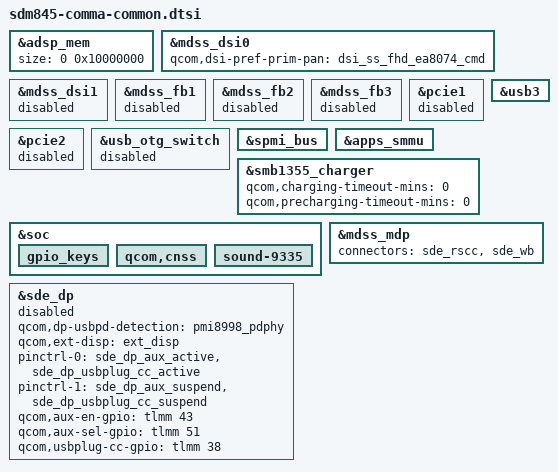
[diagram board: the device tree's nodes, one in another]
/*
 * Copyright (C) 2018, Comma.ai, Inc.
 *
 * This program is free software; you can redistribute it and/or modify
 * it under the terms of the GNU General Public License version 2 and
 * only version 2 as published by the Free Software Foundation.
 *
 * This program is distributed in the hope that it will be useful,
 * but WITHOUT ANY WARRANTY; without even the implied warranty of
 * MERCHANTABILITY or FITNESS FOR A PARTICULAR PURPOSE.  See the
 * GNU General Public License for more details.
 */

&adsp_mem {
	size = <0 0x10000000>;
};

&mdss_dsi0 {
	/delete-property/ qcom,platform-bklight-en-gpio;
};

&mdss_dsi1 {
	status = "disabled";
};

&mdss_fb1 {
	status = "disabled";
};

&mdss_fb2 {
	status = "disabled";
};

&mdss_fb3 {
	status = "disabled";
};


&pcie1 {
	status = "disabled";
};

&pcie2 {
	status = "disabled";
};


&usb3 {
	/delete-property/ vbus_dwc3-supply;
};

&usb_otg_switch {
	status = "disabled";
};

&spmi_bus {
	/delete-property/ qcom,enable-ahb-bus-workaround;
};

&apps_smmu {
	/delete-property/ qcom,no-asid-retention;
};

&smb1355_charger {
	qcom,charging-timeout-mins = <0>;
	qcom,precharging-timeout-mins = <0>;
};

&soc {
	/delete-node/ gen-vkeys;

	gpio_keys {
		/delete-node/ cam_focus;
		/delete-node/ cam_snapshot;
	};

	qcom,cnss {
		/delete-property/ qcom,wlan-ramdump-dynamic;
	};

	sound-9335 {
		/delete-property/ qcom,hph-en0-gpio;
		/delete-property/ qcom,hph-en1-gpio;
		/delete-property/ qcom,us-euro-gpios;
		/delete-property/ qcom,wsa-aux-dev-prefix;
		/delete-property/ qcom,wsa-devs;
		/delete-property/ qcom,wsa-max-devs;
	};
};

&sde_dp {
	status = "disabled";
	qcom,dp-usbpd-detection = <&pmi8998_pdphy>;
	qcom,ext-disp = <&ext_disp>;

	pinctrl-names = "mdss_dp_active", "mdss_dp_sleep";
	pinctrl-0 = <&sde_dp_aux_active &sde_dp_usbplug_cc_active>;
	pinctrl-1 = <&sde_dp_aux_suspend &sde_dp_usbplug_cc_suspend>;
	qcom,aux-en-gpio = <&tlmm 43 0>;
	qcom,aux-sel-gpio = <&tlmm 51 0>;
	qcom,usbplug-cc-gpio = <&tlmm 38 0>;
};

&mdss_dsi0 {
   qcom,dsi-pref-prim-pan = <&dsi_ss_fhd_ea8074_cmd>;

   status = "ok";
};

&mdss_mdp {
  //connectors = <&sde_rscc &sde_wb &sde_dp>;
  connectors = <&sde_rscc &sde_wb>;
  // crashes without sde_wb
  //connectors = <&sde_rscc>;
};
